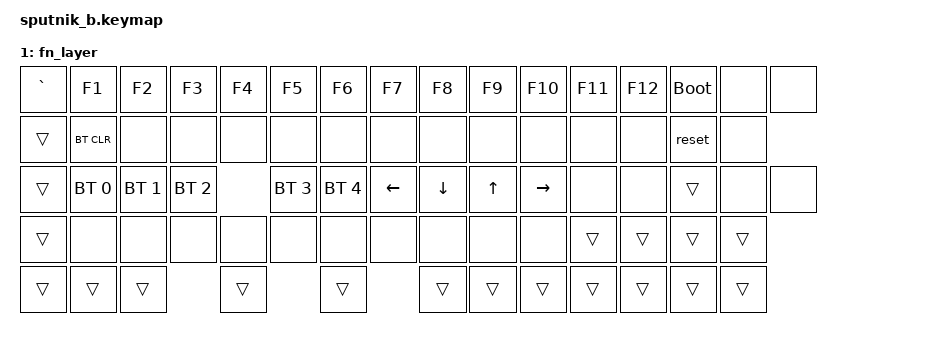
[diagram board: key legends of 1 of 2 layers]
#include <behaviors.dtsi>
#include <dt-bindings/zmk/keys.h>
#include <dt-bindings/zmk/rgb.h>
#include <dt-bindings/zmk/bt.h>

/ {
	keymap {
		compatible = "zmk,keymap";

		default_layer {
// ------------------------------------------------------------------------------------------
// | ESC |  1  |  2  |  3  |  4  |  5  |  6  |  7  |  8  |  9  |  0  |  -  |  =  |   BKSP  |   PSCR   |
// | TAB  |  Q  |  W  |  E  |  R  |  T  |  Y  |  U  |  I  |  O  |  P  |  [  |  ]  |    \   |   INS    |
// | CAPS  |  A  |  S  |  D  |  F  |  G  |  H  |  J  |  K  |  L  |  ;  |  '  |     ENTER   |   HOME   |
// |  SHIFT  |  Z  |  X  |  C  |  V  |  B  |  N  |  M  |  ,  |  .  |  /  |  SHIFT   |  UP  |   END    |
// |  CTL  |  WIN  |  ALT  |   SPACE   |  SPACE  |  SPACE  |  ALT  |  GUI  |  LEFT  | DOWN |   RGHT   |
// ------------------------------------------------------------------------------------------
			bindings = <
	&kp ESC   &kp N1   &kp N2 &kp N3 &kp N4 &kp N5 &kp N6 &kp N7 &kp   N8  &kp  N9 &kp  N0  &kp MINUS &kp EQUAL &kp DEL &kp BSPC &kp PSCRN
	&kp TAB   &kp S    &kp W  &kp E  &kp R  &kp T  &kp Y  &kp U  &kp   I   &kp  O  &kp   P  &kp LBKT  &kp RBKT          &kp BSLH &kp INS
	&kp CLCK  &kp A    &kp S  &kp D  &kp F  &kp G  &kp H  &kp J  &kp   K   &kp  L  &kp SEMI &kp SQT   &kp NON_US_BSLH   &kp RET  &kp HOME
	&kp LSHFT &kp NON_US_HASH &kp Z  &kp X  &kp C  &kp V  &kp B  &kp   N   &kp M  &kp COMMA &kp DOT  &kp FSLH &kp RSHFT &kp UP &kp END
	&kp LCTRL &kp LGUI &kp LALT      &kp SPACE     &kp SPACE     &kp SPACE        &kp RALT  &mo 1    &kp LEFT  &kp UP &kp RIGHT
			>;
		};

		fn_layer {
			bindings = <
&kp GRAVE  &kp F1     &kp F2     &kp F3     &kp F4     &kp F5     &kp F6     &kp F7     &kp F8     &kp F9     &kp F10    &kp F11    &kp F12    &bootloader   &none   &none
&trans     &bt BT_CLR &none      &none      &none      &none      &none      &none      &none      &none      &none      &none      &none      &reset        &none
&trans     &bt BT_SEL 0 &bt BT_SEL 1 &bt BT_SEL 2 &bt BT_SEL 3 &bt BT_SEL 4 &kp LEFT   &kp DOWN   &kp UP      &kp RIGHT  &none      &none      &trans        &none    &none
&trans     &none      &none      &none      &none      &none      &none      &none      &none      &none      &none      &trans     &trans     &trans        &trans
&trans     &trans     &trans                &trans                &trans                &trans     &trans     &trans     &trans     &trans     &trans        &trans
			>;
		};
	};
};


